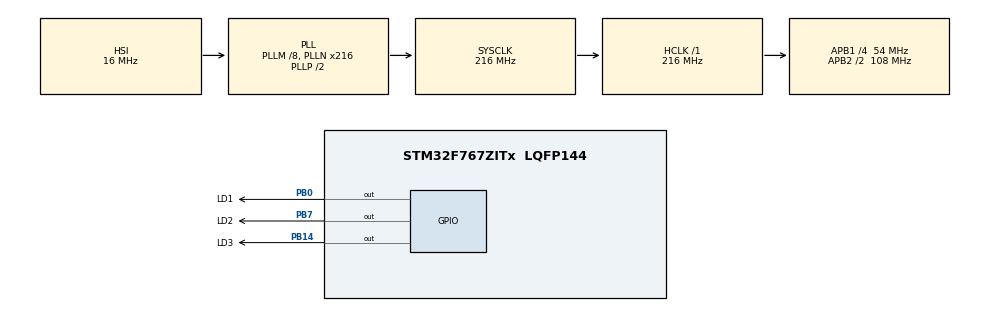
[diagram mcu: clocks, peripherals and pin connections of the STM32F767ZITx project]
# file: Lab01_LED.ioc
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Mcu.Family=STM32F7
Mcu.Name=STM32F767ZITx
Mcu.Package=LQFP144
NVIC.PriorityGroup=NVIC_PRIORITYGROUP_4
PB0.GPIO_Label=LD1
PB0.Signal=GPIO_Output
PB14.GPIO_Label=LD3
PB14.Signal=GPIO_Output
PB7.GPIO_Label=LD2
PB7.Signal=GPIO_Output
ProjectManager.HeapSize=0x200
ProjectManager.StackSize=0x400
ProjectManager.TargetToolchain=MDK-ARM V5.27
RCC.AHBFreq_Value=216000000
RCC.APB1CLKDivider=RCC_HCLK_DIV4
RCC.APB1Freq_Value=54000000
RCC.APB1TimFreq_Value=108000000
RCC.APB2CLKDivider=RCC_HCLK_DIV2
RCC.APB2Freq_Value=108000000
RCC.APB2TimFreq_Value=216000000
RCC.CortexFreq_Value=216000000
RCC.HCLKFreq_Value=216000000
RCC.HSE_VALUE=25000000
RCC.HSI_VALUE=16000000
RCC.LSE_VALUE=32768
RCC.PLLM=8
RCC.PLLN=216
RCC.SYSCLKFreq_VALUE=216000000
RCC.SYSCLKSource=RCC_SYSCLKSOURCE_PLLCLK
RCC.USBFreq_Value=216000000
RCC.VCOOutputFreq_Value=432000000
board=custom

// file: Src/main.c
/* USER CODE BEGIN Header */
/**
  ******************************************************************************
  * @file           : main.c
  * @brief          : Main program body
  ******************************************************************************
  * @attention
  *
  * <h2><center>&copy; Copyright (c) 2020 STMicroelectronics.
  * All rights reserved.</center></h2>
  *
  * This software component is licensed by ST under BSD 3-Clause license,
  * the "License"; You may not use this file except in compliance with the
  * License. You may obtain a copy of the License at:
  *                        opensource.org/licenses/BSD-3-Clause
  *
  ******************************************************************************
  */
/* USER CODE END Header */
#include "main.h"
#include "gpio.h"

/* USER CODE BEGIN PD */

/* --------------------- Change question to compile here ---------------------*/
/* ---------------------- Available question 1, 2 and 3 ----------------------*/
#define QUESTION 3

/* USER CODE END PD */

/* USER CODE BEGIN PV */
uint8_t num = 0;
/* USER CODE END PV */

void SystemClock_Config(void);
/* USER CODE BEGIN PFP */
void delay (uint32_t);
/* USER CODE END PFP */

int main(void)
{

  /* MCU Configuration--------------------------------------------------------*/

  /* Reset of all peripherals, Initializes the Flash interface and the Systick. */
  HAL_Init();

  /* Configure the system clock */
  SystemClock_Config();

  /* Initialize all configured peripherals */
  MX_GPIO_Init();

  /* Infinite loop */
  while (1)
  {

    /* USER CODE BEGIN 3 */

		if (num < 7)
			num++;
		else
			num = 0;

#if QUESTION == 1 || QUESTION == 2
		// HAL_GPIO_TogglePin(LD1_GPIO_Port, LD1_Pin);
		LD1_GPIO_Port->ODR ^= LD1_Pin;

		delay(500);
#elif QUESTION == 3
		GPIOB->ODR ^= GPIOB->ODR ^ (((num>>0&1)<<0) | ((num>>1&1)<<7) | ((num>>2&1)<<14));

		// LD1_GPIO_Port->ODR ^= LD1_Pin;
		// LD2_GPIO_Port->ODR ^= !(num >> 1 & 1) == !(LD2_GPIO_Port->ODR & LD2_Pin) ? 0 : LD2_Pin;
		// LD3_GPIO_Port->ODR ^= !(num >> 2 & 1) == !(LD3_GPIO_Port->ODR & LD3_Pin) ? 0 : LD3_Pin;

		// HAL_GPIO_WritePin(LD1_GPIO_Port, LD1_Pin, num >> 0 & 1 ? GPIO_PIN_SET : GPIO_PIN_RESET);
		// HAL_GPIO_WritePin(LD2_GPIO_Port, LD2_Pin, num >> 1 & 1 ? GPIO_PIN_SET : GPIO_PIN_RESET);
		// HAL_GPIO_WritePin(LD3_GPIO_Port, LD3_Pin, num >> 2 & 1 ? GPIO_PIN_SET : GPIO_PIN_RESET);

		delay(300);
#endif
  }
  /* USER CODE END 3 */
}

void SystemClock_Config(void)
{
  RCC_OscInitTypeDef RCC_OscInitStruct = {0};
  RCC_ClkInitTypeDef RCC_ClkInitStruct = {0};

  /** Configure the main internal regulator output voltage
  */
  __HAL_RCC_PWR_CLK_ENABLE();
  __HAL_PWR_VOLTAGESCALING_CONFIG(PWR_REGULATOR_VOLTAGE_SCALE1);
  /** Initializes the RCC Oscillators according to the specified parameters
  * in the RCC_OscInitTypeDef structure.
  */
  RCC_OscInitStruct.OscillatorType = RCC_OSCILLATORTYPE_HSI;
  RCC_OscInitStruct.HSIState = RCC_HSI_ON;
  RCC_OscInitStruct.HSICalibrationValue = RCC_HSICALIBRATION_DEFAULT;
  RCC_OscInitStruct.PLL.PLLState = RCC_PLL_ON;
  RCC_OscInitStruct.PLL.PLLSource = RCC_PLLSOURCE_HSI;
  RCC_OscInitStruct.PLL.PLLM = 8;
  RCC_OscInitStruct.PLL.PLLN = 216;
  RCC_OscInitStruct.PLL.PLLP = RCC_PLLP_DIV2;
  RCC_OscInitStruct.PLL.PLLQ = 2;
  if (HAL_RCC_OscConfig(&RCC_OscInitStruct) != HAL_OK)
  {
    Error_Handler();
  }
  /** Activate the Over-Drive mode
  */
  if (HAL_PWREx_EnableOverDrive() != HAL_OK)
  {
    Error_Handler();
  }
  /** Initializes the CPU, AHB and APB buses clocks
  */
  RCC_ClkInitStruct.ClockType = RCC_CLOCKTYPE_HCLK|RCC_CLOCKTYPE_SYSCLK
                              |RCC_CLOCKTYPE_PCLK1|RCC_CLOCKTYPE_PCLK2;
  RCC_ClkInitStruct.SYSCLKSource = RCC_SYSCLKSOURCE_PLLCLK;
  RCC_ClkInitStruct.AHBCLKDivider = RCC_SYSCLK_DIV1;
  RCC_ClkInitStruct.APB1CLKDivider = RCC_HCLK_DIV4;
  RCC_ClkInitStruct.APB2CLKDivider = RCC_HCLK_DIV2;

  if (HAL_RCC_ClockConfig(&RCC_ClkInitStruct, FLASH_LATENCY_7) != HAL_OK)
  {
    Error_Handler();
  }
}

/* USER CODE BEGIN 4 */
void delay(uint32_t ms)
{
	volatile uint32_t i, j;
#if QUESTION == 1 || QUESTION == 3
	#define ROUND 7500
#elif QUESTION == 2
	#define ROUND 36251
#endif
	for (i = 0; i < ms; i++)
		for (j = 0; j < ROUND; j++)
			;
	return ;
}
/* USER CODE END 4 */

void Error_Handler(void)
{
}

/************************ (C) COPYRIGHT STMicroelectronics *****END OF FILE****/
